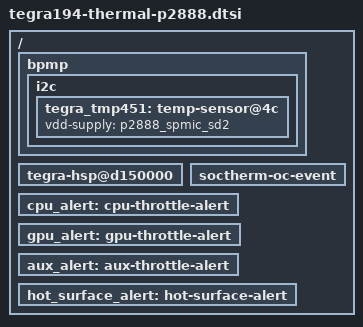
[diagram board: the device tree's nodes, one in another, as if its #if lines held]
/*
 * Copyright (c) 2017-2022, NVIDIA CORPORATION.  All rights reserved.
 *
 * This program is free software; you can redistribute it and/or modify it
 * under the terms and conditions of the GNU General Public License,
 * version 2, as published by the Free Software Foundation.
 *
 * This program is distributed in the hope it will be useful, but WITHOUT
 * ANY WARRANTY; without even the implied warranty of MERCHANTABILITY or
 * FITNESS FOR A PARTICULAR PURPOSE.  See the GNU General Public License for
 * more details.
 *
 * You should have received a copy of the GNU General Public License
 * along with this program.  If not, see <http://www.gnu.org/licenses/>.
 */

#include <t19x-common-platforms/tegra194-thermal.dtsi>
#include <t19x-common-platforms/tegra194-thermal-userspace-alert.dtsi>
#include "tegra194-spmic-p2888-0001.dtsi"
/ {
#if TEGRA_BPMP_FW_DT_VERSION >= DT_VERSION_2
	bpmp { i2c {
#else
	bpmp_i2c {
#endif
		tegra_tmp451: temp-sensor@4c {
			vdd-supply = <&p2888_spmic_sd2>;
		};
#if TEGRA_BPMP_FW_DT_VERSION >= DT_VERSION_2
	}; };
#else
	};
#endif

	tegra-hsp@d150000 {
		status = "okay";
	};

	soctherm-oc-event {
		status = "okay";
	};

	cpu_alert: cpu-throttle-alert {
		status = "okay";
	};

	gpu_alert: gpu-throttle-alert {
		status = "okay";
	};

	aux_alert: aux-throttle-alert {
		status = "okay";
	};

	hot_surface_alert: hot-surface-alert {
		status = "okay";
	};
};

